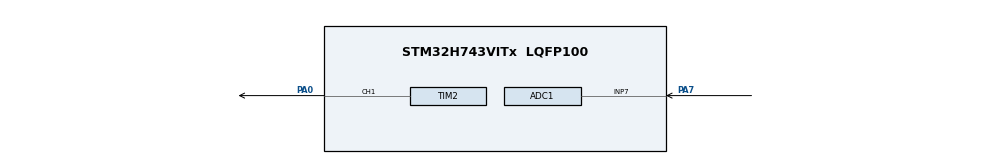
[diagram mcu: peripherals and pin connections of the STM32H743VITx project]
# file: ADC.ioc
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ADC1.Channel-0\#ChannelRegularConversion=ADC_CHANNEL_7
ADC1.NbrOfConversionFlag=1
ADC1.OffsetNumber-0\#ChannelRegularConversion=ADC_OFFSET_NONE
ADC1.OffsetSignedSaturation-0\#ChannelRegularConversion=DISABLE
ADC1.Rank-0\#ChannelRegularConversion=1
ADC1.SamplingTime-0\#ChannelRegularConversion=ADC_SAMPLETIME_1CYCLE_5
ADC1.master=1
CORTEX_M7.default_mode_Activation=1
Mcu.Family=STM32H7
Mcu.Name=STM32H743VITx
Mcu.Package=LQFP100
NVIC.PriorityGroup=NVIC_PRIORITYGROUP_4
PA0.Signal=S_TIM2_CH1_ETR
PA7.Signal=ADCx_INP7
PC14-OSC32_IN\ (OSC32_IN).Mode=LSE-External-Oscillator
PC14-OSC32_IN\ (OSC32_IN).Signal=RCC_OSC32_IN
PC15-OSC32_OUT\ (OSC32_OUT).Mode=LSE-External-Oscillator
PC15-OSC32_OUT\ (OSC32_OUT).Signal=RCC_OSC32_OUT
PH0-OSC_IN\ (PH0).Mode=HSE-External-Oscillator
PH0-OSC_IN\ (PH0).Signal=RCC_OSC_IN
PH1-OSC_OUT\ (PH1).Mode=HSE-External-Oscillator
PH1-OSC_OUT\ (PH1).Signal=RCC_OSC_OUT
ProjectManager.HeapSize=0x200
ProjectManager.StackSize=0x400
ProjectManager.TargetToolchain=STM32CubeIDE
RCC.ADCFreq_Value=80000000
RCC.APB1Freq_Value=120000000
RCC.APB2Freq_Value=120000000
RCC.APB3Freq_Value=120000000
RCC.APB4Freq_Value=120000000
RCC.CortexFreq_Value=480000000
RCC.D1PPRE=RCC_APB3_DIV2
RCC.D2PPRE1=RCC_APB1_DIV2
RCC.D2PPRE2=RCC_APB2_DIV2
RCC.D3PPRE=RCC_APB4_DIV2
RCC.DIVM1=4
RCC.DIVM2=4
RCC.DIVN1=60
RCC.DIVN2=10
RCC.HCLKFreq_Value=240000000
RCC.HPRE=RCC_HCLK_DIV2
RCC.PLL2FRACN=0
RCC.PLL3FRACN=0
RCC.PLLFRACN=0
RCC.SYSCLKFreq_VALUE=480000000
RCC.SYSCLKSource=RCC_SYSCLKSOURCE_PLLCLK
RCC.USBFreq_Value=480000000
SH.ADCx_INP7.0=ADC1_INP7,IN7-Single-Ended
SH.S_TIM2_CH1_ETR.0=TIM2_CH1,PWM Generation1 CH1
TIM2.Channel-PWM\ Generation1\ CH1=TIM_CHANNEL_1
VP_MEMORYMAP_VS_MEMORYMAP.Mode=CurAppReg
VP_TIM2_VS_ClockSourceINT.Mode=Internal
board=custom

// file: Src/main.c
/* USER CODE BEGIN Header */
/**
  ******************************************************************************
  * @file           : main.c
  * @brief          : Main program body
  ******************************************************************************
  * @attention
  *
  * Copyright (c) 2026 STMicroelectronics.
  * All rights reserved.
  *
  * This software is licensed under terms that can be found in the LICENSE file
  * in the root directory of this software component.
  * If no LICENSE file comes with this software, it is provided AS-IS.
  *
  ******************************************************************************
  */
/* USER CODE END Header */
#include "main.h"

ADC_HandleTypeDef hadc1;

TIM_HandleTypeDef htim2;

void SystemClock_Config(void);
static void MPU_Config(void);
static void MX_GPIO_Init(void);
static void MX_ADC1_Init(void);
static void MX_TIM2_Init(void);

int main(void)
{

  /* USER CODE BEGIN 1 */
  uint16_t AD_RES = 0;

  /* USER CODE END 1 */

  /* MPU Configuration--------------------------------------------------------*/
  MPU_Config();

  /* MCU Configuration--------------------------------------------------------*/

  /* Reset of all peripherals, Initializes the Flash interface and the Systick. */
  HAL_Init();

  /* Configure the system clock */
  SystemClock_Config();

  /* Initialize all configured peripherals */
  MX_GPIO_Init();
  MX_ADC1_Init();
  MX_TIM2_Init();
  /* USER CODE BEGIN 2 */
  HAL_TIM_PWM_Start(&htim2, TIM_CHANNEL_1);
  HAL_ADCEx_Calibration_Start(&hadc1, ADC_CALIB_OFFSET, ADC_SINGLE_ENDED);
  /* USER CODE END 2 */

  /* Infinite loop */
  while (1)
  {
	HAL_ADC_Start(&hadc1);
	HAL_ADC_PollForConversion(&hadc1, 1);
	AD_RES = HAL_ADC_GetValue(&hadc1);
	TIM2->CCR1 = (AD_RES << 4);
	HAL_Delay(1);
  }
}

void SystemClock_Config(void)
{
  RCC_OscInitTypeDef RCC_OscInitStruct = {0};
  RCC_ClkInitTypeDef RCC_ClkInitStruct = {0};

  /** Supply configuration update enable
  */
  HAL_PWREx_ConfigSupply(PWR_LDO_SUPPLY);

  /** Configure the main internal regulator output voltage
  */
  __HAL_PWR_VOLTAGESCALING_CONFIG(PWR_REGULATOR_VOLTAGE_SCALE0);

  while(!__HAL_PWR_GET_FLAG(PWR_FLAG_VOSRDY)) {}

  /** Initializes the RCC Oscillators according to the specified parameters
  * in the RCC_OscInitTypeDef structure.
  */
  RCC_OscInitStruct.OscillatorType = RCC_OSCILLATORTYPE_HSI;
  RCC_OscInitStruct.HSIState = RCC_HSI_DIV1;
  RCC_OscInitStruct.HSICalibrationValue = RCC_HSICALIBRATION_DEFAULT;
  RCC_OscInitStruct.PLL.PLLState = RCC_PLL_ON;
  RCC_OscInitStruct.PLL.PLLSource = RCC_PLLSOURCE_HSI;
  RCC_OscInitStruct.PLL.PLLM = 4;
  RCC_OscInitStruct.PLL.PLLN = 60;
  RCC_OscInitStruct.PLL.PLLP = 2;
  RCC_OscInitStruct.PLL.PLLQ = 2;
  RCC_OscInitStruct.PLL.PLLR = 2;
  RCC_OscInitStruct.PLL.PLLRGE = RCC_PLL1VCIRANGE_3;
  RCC_OscInitStruct.PLL.PLLVCOSEL = RCC_PLL1VCOWIDE;
  RCC_OscInitStruct.PLL.PLLFRACN = 0;
  if (HAL_RCC_OscConfig(&RCC_OscInitStruct) != HAL_OK)
  {
    Error_Handler();
  }

  /** Initializes the CPU, AHB and APB buses clocks
  */
  RCC_ClkInitStruct.ClockType = RCC_CLOCKTYPE_HCLK|RCC_CLOCKTYPE_SYSCLK
                              |RCC_CLOCKTYPE_PCLK1|RCC_CLOCKTYPE_PCLK2
                              |RCC_CLOCKTYPE_D3PCLK1|RCC_CLOCKTYPE_D1PCLK1;
  RCC_ClkInitStruct.SYSCLKSource = RCC_SYSCLKSOURCE_PLLCLK;
  RCC_ClkInitStruct.SYSCLKDivider = RCC_SYSCLK_DIV1;
  RCC_ClkInitStruct.AHBCLKDivider = RCC_HCLK_DIV2;
  RCC_ClkInitStruct.APB3CLKDivider = RCC_APB3_DIV2;
  RCC_ClkInitStruct.APB1CLKDivider = RCC_APB1_DIV2;
  RCC_ClkInitStruct.APB2CLKDivider = RCC_APB2_DIV2;
  RCC_ClkInitStruct.APB4CLKDivider = RCC_APB4_DIV2;

  if (HAL_RCC_ClockConfig(&RCC_ClkInitStruct, FLASH_LATENCY_4) != HAL_OK)
  {
    Error_Handler();
  }
}

static void MX_ADC1_Init(void)
{

  ADC_MultiModeTypeDef multimode = {0};
  ADC_ChannelConfTypeDef sConfig = {0};

  /** Common config
  */
  hadc1.Instance = ADC1;
  hadc1.Init.ClockPrescaler = ADC_CLOCK_ASYNC_DIV1;
  hadc1.Init.Resolution = ADC_RESOLUTION_16B;
  hadc1.Init.ScanConvMode = ADC_SCAN_DISABLE;
  hadc1.Init.EOCSelection = ADC_EOC_SINGLE_CONV;
  hadc1.Init.LowPowerAutoWait = DISABLE;
  hadc1.Init.ContinuousConvMode = DISABLE;
  hadc1.Init.NbrOfConversion = 1;
  hadc1.Init.DiscontinuousConvMode = DISABLE;
  hadc1.Init.ExternalTrigConv = ADC_SOFTWARE_START;
  hadc1.Init.ExternalTrigConvEdge = ADC_EXTERNALTRIGCONVEDGE_NONE;
  hadc1.Init.ConversionDataManagement = ADC_CONVERSIONDATA_DR;
  hadc1.Init.Overrun = ADC_OVR_DATA_PRESERVED;
  hadc1.Init.LeftBitShift = ADC_LEFTBITSHIFT_NONE;
  hadc1.Init.OversamplingMode = DISABLE;
  hadc1.Init.Oversampling.Ratio = 1;
  if (HAL_ADC_Init(&hadc1) != HAL_OK)
  {
    Error_Handler();
  }

  /** Configure the ADC multi-mode
  */
  multimode.Mode = ADC_MODE_INDEPENDENT;
  if (HAL_ADCEx_MultiModeConfigChannel(&hadc1, &multimode) != HAL_OK)
  {
    Error_Handler();
  }

  /** Configure Regular Channel
  */
  sConfig.Channel = ADC_CHANNEL_7;
  sConfig.Rank = ADC_REGULAR_RANK_1;
  sConfig.SamplingTime = ADC_SAMPLETIME_1CYCLE_5;
  sConfig.SingleDiff = ADC_SINGLE_ENDED;
  sConfig.OffsetNumber = ADC_OFFSET_NONE;
  sConfig.Offset = 0;
  sConfig.OffsetSignedSaturation = DISABLE;
  if (HAL_ADC_ConfigChannel(&hadc1, &sConfig) != HAL_OK)
  {
    Error_Handler();
  }

}

static void MX_TIM2_Init(void)
{

  TIM_ClockConfigTypeDef sClockSourceConfig = {0};
  TIM_MasterConfigTypeDef sMasterConfig = {0};
  TIM_OC_InitTypeDef sConfigOC = {0};

  htim2.Instance = TIM2;
  htim2.Init.Prescaler = 0;
  htim2.Init.CounterMode = TIM_COUNTERMODE_UP;
  htim2.Init.Period = 4294967295;
  htim2.Init.ClockDivision = TIM_CLOCKDIVISION_DIV1;
  htim2.Init.AutoReloadPreload = TIM_AUTORELOAD_PRELOAD_DISABLE;
  if (HAL_TIM_Base_Init(&htim2) != HAL_OK)
  {
    Error_Handler();
  }
  sClockSourceConfig.ClockSource = TIM_CLOCKSOURCE_INTERNAL;
  if (HAL_TIM_ConfigClockSource(&htim2, &sClockSourceConfig) != HAL_OK)
  {
    Error_Handler();
  }
  if (HAL_TIM_PWM_Init(&htim2) != HAL_OK)
  {
    Error_Handler();
  }
  sMasterConfig.MasterOutputTrigger = TIM_TRGO_RESET;
  sMasterConfig.MasterSlaveMode = TIM_MASTERSLAVEMODE_DISABLE;
  if (HAL_TIMEx_MasterConfigSynchronization(&htim2, &sMasterConfig) != HAL_OK)
  {
    Error_Handler();
  }
  sConfigOC.OCMode = TIM_OCMODE_PWM1;
  sConfigOC.Pulse = 0;
  sConfigOC.OCPolarity = TIM_OCPOLARITY_HIGH;
  sConfigOC.OCFastMode = TIM_OCFAST_DISABLE;
  if (HAL_TIM_PWM_ConfigChannel(&htim2, &sConfigOC, TIM_CHANNEL_1) != HAL_OK)
  {
    Error_Handler();
  }
  HAL_TIM_MspPostInit(&htim2);

}

static void MX_GPIO_Init(void)
{

  /* GPIO Ports Clock Enable */
  __HAL_RCC_GPIOC_CLK_ENABLE();
  __HAL_RCC_GPIOH_CLK_ENABLE();
  __HAL_RCC_GPIOA_CLK_ENABLE();

}

 /* MPU Configuration */

void MPU_Config(void)
{
  MPU_Region_InitTypeDef MPU_InitStruct = {0};

  /* Disables the MPU */
  HAL_MPU_Disable();

  /** Initializes and configures the Region and the memory to be protected
  */
  MPU_InitStruct.Enable = MPU_REGION_ENABLE;
  MPU_InitStruct.Number = MPU_REGION_NUMBER0;
  MPU_InitStruct.BaseAddress = 0x0;
  MPU_InitStruct.Size = MPU_REGION_SIZE_4GB;
  MPU_InitStruct.SubRegionDisable = 0x87;
  MPU_InitStruct.TypeExtField = MPU_TEX_LEVEL0;
  MPU_InitStruct.AccessPermission = MPU_REGION_NO_ACCESS;
  MPU_InitStruct.DisableExec = MPU_INSTRUCTION_ACCESS_DISABLE;
  MPU_InitStruct.IsShareable = MPU_ACCESS_SHAREABLE;
  MPU_InitStruct.IsCacheable = MPU_ACCESS_NOT_CACHEABLE;
  MPU_InitStruct.IsBufferable = MPU_ACCESS_NOT_BUFFERABLE;

  HAL_MPU_ConfigRegion(&MPU_InitStruct);
  /* Enables the MPU */
  HAL_MPU_Enable(MPU_PRIVILEGED_DEFAULT);

}

void Error_Handler(void)
{
  __disable_irq();
  while (1)
  {
  }
}
